# STM32G071RBT6 register map
File version: 1.0
STM32G071C6T6,STM32G071C6U3,STM32G071C6U6,STM32G071C6U7,STM32G071C8T3,STM32G071C8T6,STM32G071C8T7,STM32G071C8U3,STM32G071C8U6,STM32G071C8U7,STM32G071CBT3,STM32G071CBT6,STM32G071CBT7,STM32G071CBU3,STM32G071CBU6,STM32G071CBU7,STM32G071EBY6,STM32G071G6U3,STM32G071G6U6,STM32G071G6U7,STM32G071G8U6,STM32G071G8U6N,STM32G071GBU3,STM32G071GBU3N,STM32G071GBU6,STM32G071GBU6N,STM32G071GBU7,STM32G071GBU7N,STM32G071K6T6,STM32G071K6U3,STM32G071K6U6,STM32G071K6U7,STM32G071K8T3,STM32G071K8T3N,STM32G071K8T6,STM32G071K8T6N,STM32G071K8T7,STM32G071K8T7N,STM32G071K8U3,STM32G071K8U3N,STM32G071K8U6,STM32G071K8U6N,STM32G071K8U7,STM32G071K8U7N,STM32G071KBT3,STM32G071KBT3N,STM32G071KBT6,STM32G071KBT6N,STM32G071KBT7,STM32G071KBT7N,STM32G071KBU3,STM32G071KBU3N,STM32G071KBU6,STM32G071KBU6N,STM32G071KBU7,STM32G071KBU7N,STM32G071R6T6,STM32G071R8T6,STM32G071RBI6,STM32G071RBT6
Registers are 32-bit, access not given, reset 0x0 unless marked. A register's access mark holds for its fields unless they carry their own. Offsets are from the block's base; lines under a group give offsets from that group; [hi:lo] are bit positions; {n}, {i} and the like mark numbered series; 'fields as' and 'values as' point back to an identical list; <NAME> marks a mode.

## Memory map
0x40000000 TIM2
0x40000400 TIM3
0x40001000 TIM6
0x40001400 TIM7
0x40002000 TIM14
0x40002800 RTC
0x40002C00 WWDG
0x40003000 IWDG
0x40003800 SPI2
0x40004400 USART2
0x40004800 USART3
0x40004C00 USART4
0x40005400 I2C1
0x40005800 I2C2
0x40007000 PWR
0x40007400 DAC1
0x40007800 CEC
0x40007C00 LPTIM1
0x40008000 LPUART1
0x40009400 LPTIM2
0x4000A000 UCPD1
0x4000A400 UCPD2
0x4000B000 TAMP
0x40010000 SYSCFG
0x40010030 VREFBUF
0x40010200 COMP1
0x40010200 COMP12_COMMON
0x40010204 COMP2
0x40012400 ADC1
0x40012C00 TIM1
0x40013000 SPI1
0x40013800 USART1
0x40014000 TIM15
0x40014400 TIM16
0x40014800 TIM17
0x40015800 DBG
0x40020000 DMA1
0x40020800 DMAMUX1
0x40021000 RCC
0x40021800 EXTI
0x40022000 FLASH
0x40023000 CRC
0x50000000 GPIOA
0x50000400 GPIOB
0x50000800 GPIOC
0x50000C00 GPIOD
0x50001400 GPIOF

## TIM2
Base 0x40000000
Same registers: TIM3 0x40000400, TIM6 0x40001000, TIM7 0x40001400, TIM14 0x40002000, TIM1 0x40012C00, TIM15 0x40014000, TIM16 0x40014400, TIM17 0x40014800
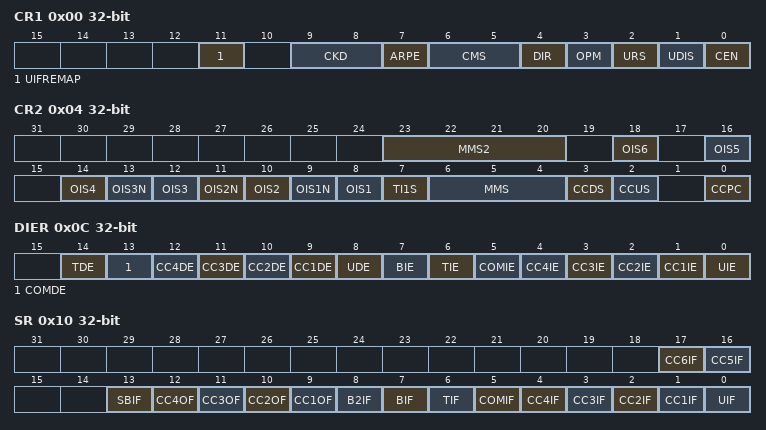
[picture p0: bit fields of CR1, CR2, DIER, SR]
0x00 CR1
  [11] UIFREMAP, [9:8] CKD, [7] ARPE, [6:5] CMS, [4] DIR, [3] OPM, [2] URS, [1] UDIS, [0] CEN
0x04 CR2
  [23:20] MMS2, [2n+6] OIS{n} (n=1..6), [13] OIS3N, [11] OIS2N, [9] OIS1N, [7] TI1S, [6:4] MMS, [3] CCDS, [2] CCUS, [0] CCPC
0x08 SMCR
  [15] ETP, [14] ECE, [13:12] ETPS, [11:8] ETF, [7] MSM, [21:4] TS, [3] OCCS, [16:0] SMS
0x0C DIER
  [14] TDE, [13] COMDE, [n+8] CC{n}DE (n=1..4), [8] UDE, [7] BIE, [6] TIE, [5] COMIE, [n] CC{n}IE (n=1..4), [0] UIE
0x10 SR
  [17] CC6IF, [16] CC5IF, [13] SBIF, [n+8] CC{n}OF (n=1..4), [8] B2IF, [7] BIF, [6] TIF, [5] COMIF, [n] CC{n}IF (n=1..4), [0] UIF
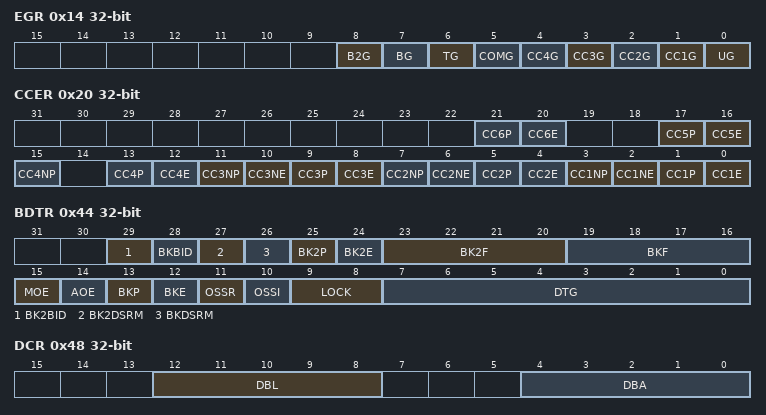
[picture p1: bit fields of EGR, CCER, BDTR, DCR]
0x14 EGR
  [8] B2G, [7] BG, [6] TG, [5] COMG, [n] CC{n}G (n=1..4), [0] UG
0x18 CCMR1
  [15] OC2CE, [24:12] OC2M, [11] OC2PE, [10] OC2FE, [9:8] CC2S, [7] OC1CE, [16:4] OC1M, [3] OC1PE, [2] OC1FE, [1:0] CC1S
0x1C CCMR2
  [15] OC4CE, [24:12] OC4M, [11] OC4PE, [10] OC4FE, [9:8] CC4S, [7] OC3CE, [16:4] OC3M, [3] OC3PE, [2] OC3FE, [1:0] CC3S
0x20 CCER
  [4n-3] CC{n}P (n=1..6), [4n-4] CC{n}E (n=1..6), [4n-1] CC{n}NP (n=1..4), [10] CC3NE, [6] CC2NE, [2] CC1NE
0x24 CNT
  [31] UIFCPY, [31:0] CNT
0x28 PSC
  [15:0] PSC
0x2C ARR
0x30 RCR
  [15:0] REP
{0x30+4i} CCR{i} (i=1..4)
  [15:0] CCR{i}
0x44 BDTR
  [29] BK2BID, [28] BKBID, [27] BK2DSRM, [26] BKDSRM, [25] BK2P, [24] BK2E, [23:20] BK2F, [19:16] BKF, [15] MOE, [14] AOE, [13] BKP, [12] BKE, [11] OSSR, [10] OSSI, [9:8] LOCK, [7:0] DTG
0x48 DCR
  [12:8] DBL, [4:0] DBA
0x4C DMAR
  [15:0] DMAB
0x50 OR1
0x54 CCMR3
  [15] OC6CE, [24:12] OC6M, [11] OC6PE, [10] OC6FE, [7] OC5CE, [16:4] OC5M, [3] OC5PE, [2] OC5FE
0x58 CCR5
  [31] GC5C3, [30] GC5C2, [29] GC5C1, [31:0] CCR5
0x5C CCR6
  [15:0] CCR6
0x60 AF1
0x64 AF2
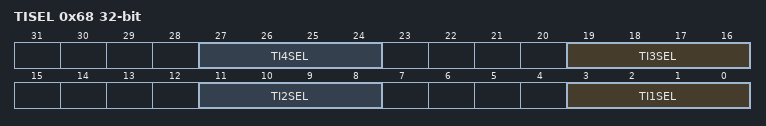
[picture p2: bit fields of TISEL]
0x68 TISEL
  [8n-5:8n-8] TI{n}SEL (n=1..4)

## RTC
Base 0x40002800
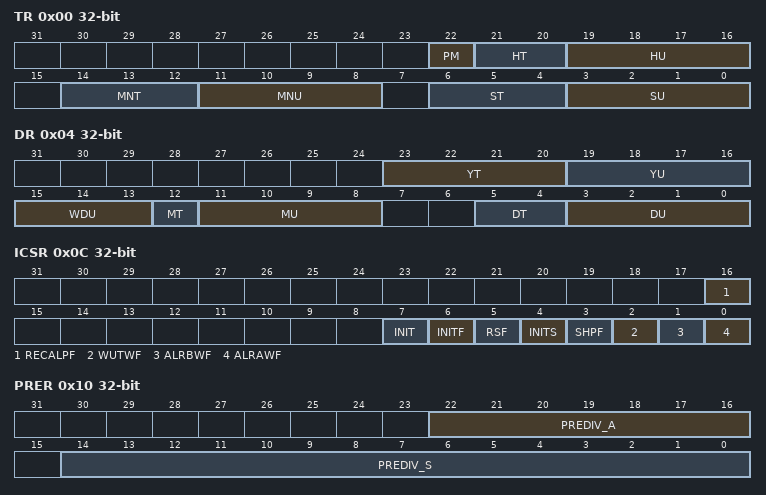
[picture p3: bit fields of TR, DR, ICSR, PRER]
0x00 TR
  [22] PM, [21:20] HT, [19:16] HU, [14:12] MNT, [11:8] MNU, [6:4] ST, [3:0] SU
0x04 DR
  [23:20] YT, [19:16] YU, [15:13] WDU, [12] MT, [11:8] MU, [5:4] DT, [3:0] DU
0x08 SSR
  [15:0] SS
0x0C ICSR
  [16] RECALPF, [7] INIT, [6] INITF, [5] RSF, [4] INITS, [3] SHPF, [2] WUTWF, [1] ALRBWF, [0] ALRAWF
0x10 PRER
  [22:16] PREDIV_A, [14:0] PREDIV_S
0x14 WUTR
  [15:0] WUT
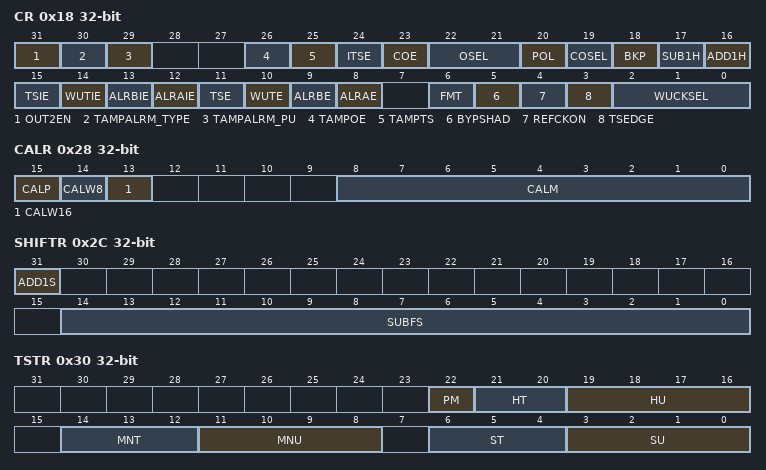
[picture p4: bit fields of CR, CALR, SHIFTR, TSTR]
0x18 CR
  [31] OUT2EN, [30] TAMPALRM_TYPE, [29] TAMPALRM_PU, [26] TAMPOE, [25] TAMPTS, [24] ITSE, [23] COE, [22:21] OSEL, [20] POL, [19] COSEL, [18] BKP, [17] SUB1H, [16] ADD1H, [15] TSIE, [14] WUTIE, [13] ALRBIE, [12] ALRAIE, [11] TSE, [10] WUTE, [9] ALRBE, [8] ALRAE, [6] FMT, [5] BYPSHAD, [4] REFCKON, [3] TSEDGE, [2:0] WUCKSEL
0x24 WPR
  [7:0] KEY
0x28 CALR
  [15] CALP, [14] CALW8, [13] CALW16, [8:0] CALM
0x2C SHIFTR
  [31] ADD1S, [14:0] SUBFS
0x30 TSTR
  fields as TR
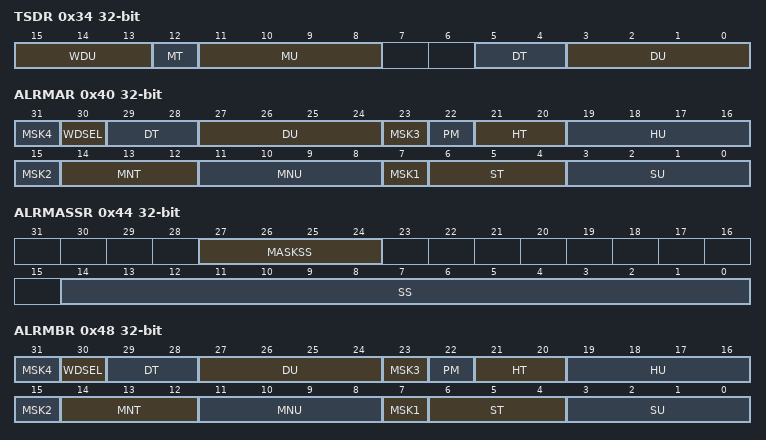
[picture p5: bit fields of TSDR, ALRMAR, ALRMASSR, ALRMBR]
0x34 TSDR
  [15:13] WDU, [12] MT, [11:8] MU, [5:4] DT, [3:0] DU
0x38 TSSSR
  [15:0] SS
0x40 ALRMAR
  [8n-1] MSK{n} (n=1..4), [30] WDSEL, [29:28] DT, [27:24] DU, [22] PM, [21:20] HT, [19:16] HU, [14:12] MNT, [11:8] MNU, [6:4] ST, [3:0] SU
0x44 ALRMASSR
  [27:24] MASKSS, [14:0] SS
0x48 ALRMBR
  fields as ALRMAR
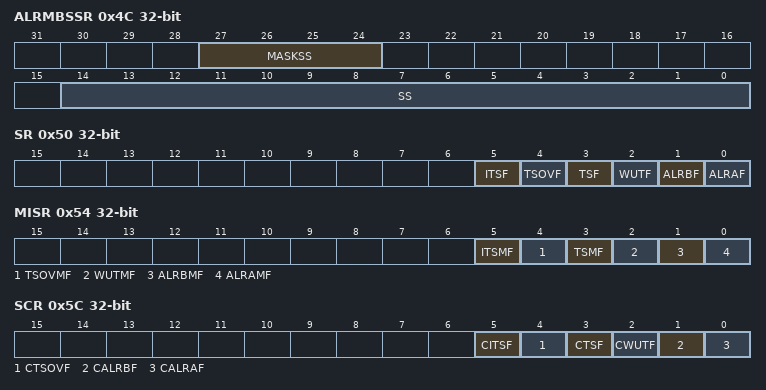
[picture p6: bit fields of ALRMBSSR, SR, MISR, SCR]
0x4C ALRMBSSR
  [27:24] MASKSS, [14:0] SS
0x50 SR
  [5] ITSF, [4] TSOVF, [3] TSF, [2] WUTF, [1] ALRBF, [0] ALRAF
0x54 MISR
  [5] ITSMF, [4] TSOVMF, [3] TSMF, [2] WUTMF, [1] ALRBMF, [0] ALRAMF
0x5C SCR
  [5] CITSF, [4] CTSOVF, [3] CTSF, [2] CWUTF, [1] CALRBF, [0] CALRAF
0x60 OR
